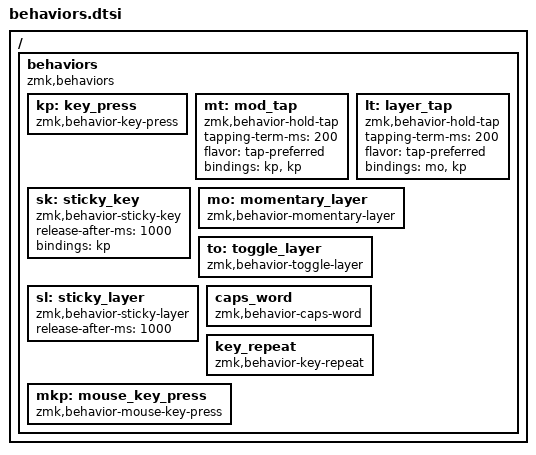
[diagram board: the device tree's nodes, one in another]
/*
 * Copyright (c) 2020 The ZMK Contributors
 *
 * SPDX-License-Identifier: MIT
 */

#include <dt-bindings/zmk/keys.h>
#include <dt-bindings/zmk/bt.h>
#include <dt-bindings/zmk/mouse.h>

/ {
    behaviors {
        compatible = "zmk,behaviors";

        /* Default behaviors */
        kp: key_press {
            compatible = "zmk,behavior-key-press";
            #binding-cells = <1>;
        };

        mt: mod_tap {
            compatible = "zmk,behavior-hold-tap";
            #binding-cells = <2>;
            tapping-term-ms = <200>;
            flavor = "tap-preferred";
            bindings = <&kp>, <&kp>;
        };

        lt: layer_tap {
            compatible = "zmk,behavior-hold-tap";
            #binding-cells = <2>;
            tapping-term-ms = <200>;
            flavor = "tap-preferred";
            bindings = <&mo>, <&kp>;
        };

        sk: sticky_key {
            compatible = "zmk,behavior-sticky-key";
            #binding-cells = <1>;
            release-after-ms = <1000>;
            bindings = <&kp>;
        };

        mo: momentary_layer {
            compatible = "zmk,behavior-momentary-layer";
            #binding-cells = <1>;
        };

        to: toggle_layer {
            compatible = "zmk,behavior-toggle-layer";
            #binding-cells = <1>;
        };

        sl: sticky_layer {
            compatible = "zmk,behavior-sticky-layer";
            #binding-cells = <1>;
            release-after-ms = <1000>;
        };

        caps_word: caps_word {
            compatible = "zmk,behavior-caps-word";
            #binding-cells = <0>;
        };

        key_repeat: key_repeat {
            compatible = "zmk,behavior-key-repeat";
            #binding-cells = <0>;
        };

        mkp: mouse_key_press {
            compatible = "zmk,behavior-mouse-key-press";
            #binding-cells = <1>;
        };
    };
}; 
